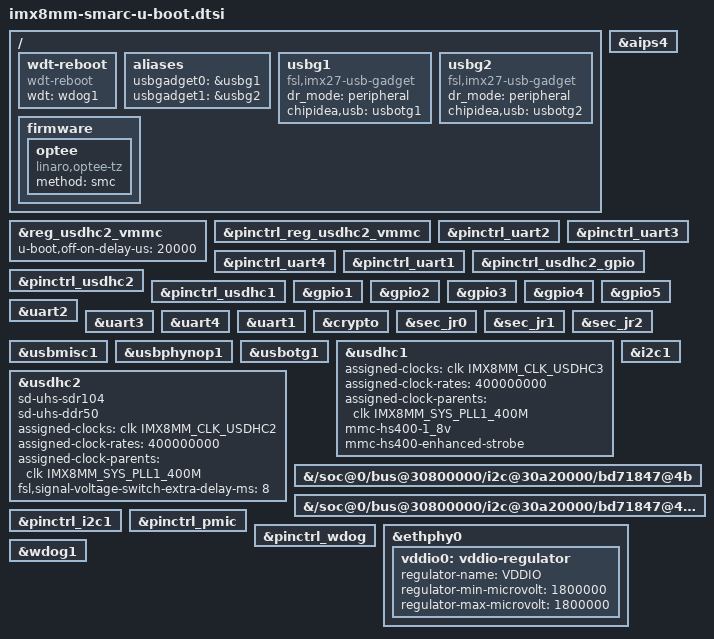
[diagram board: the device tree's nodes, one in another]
// SPDX-License-Identifier: GPL-2.0+
/*
 * Copyright 2019, 2021 NXP
 */

#include "imx8mm-u-boot.dtsi"

/ {
	wdt-reboot {
		compatible = "wdt-reboot";
		wdt = <&wdog1>;
		bootph-pre-ram;
	};

	aliases {
		usbgadget0 = &usbg1;
		usbgadget1 = &usbg2;
	};

	usbg1: usbg1 {
		compatible = "fsl,imx27-usb-gadget";
		dr_mode = "peripheral";
		chipidea,usb = <&usbotg1>;
		status = "okay";
	};

	usbg2: usbg2 {
		compatible = "fsl,imx27-usb-gadget";
		dr_mode = "peripheral";
		chipidea,usb = <&usbotg2>;
		status = "okay";
	};

	firmware {
		optee {
			compatible = "linaro,optee-tz";
			method = "smc";
		};
	};
};

&aips4 {
	bootph-pre-ram;
};

&reg_usdhc2_vmmc {
	u-boot,off-on-delay-us = <20000>;
	bootph-pre-ram;
};

&pinctrl_reg_usdhc2_vmmc {
	bootph-pre-ram;
};

&pinctrl_uart2 {
	bootph-pre-ram;
};

&pinctrl_uart3 {
	bootph-pre-ram;
};

&pinctrl_uart4 {
	bootph-pre-ram;
};

&pinctrl_uart1 {
	bootph-pre-ram;
};

&pinctrl_usdhc2_gpio {
	bootph-pre-ram;
};

&pinctrl_usdhc2 {
	bootph-pre-ram;
};

&pinctrl_usdhc1 {
	bootph-pre-ram;
};

&gpio1 {
	bootph-pre-ram;
};

&gpio2 {
	bootph-pre-ram;
};

&gpio3 {
	bootph-pre-ram;
};

&gpio4 {
	bootph-pre-ram;
};

&gpio5 {
	u-boot,dm-spl;
};

&uart2 {
	u-boot,dm-spl;
};

&uart3 {
	u-boot,dm-spl;
};

&uart4 {
	u-boot,dm-spl;
};

&uart1 {
	u-boot,dm-spl;
};

&crypto {
	u-boot,dm-spl;
};

&sec_jr0 {
	u-boot,dm-spl;
};

&sec_jr1 {
	u-boot,dm-spl;
};

&sec_jr2 {
	u-boot,dm-spl;
};

&usbmisc1 {
	u-boot,dm-spl;
};

&usbphynop1 {
	u-boot,dm-spl;
};

&usbotg1 {
	u-boot,dm-spl;
};

&usdhc1 {
	u-boot,dm-spl;
	assigned-clocks = <&clk IMX8MM_CLK_USDHC1>;
	assigned-clock-rates = <400000000>;
	assigned-clock-parents = <&clk IMX8MM_SYS_PLL1_400M>;
};

&usdhc2 {
	u-boot,dm-spl;
	sd-uhs-sdr104;
	sd-uhs-ddr50;
	assigned-clocks = <&clk IMX8MM_CLK_USDHC2>;
	assigned-clock-rates = <400000000>;
	assigned-clock-parents = <&clk IMX8MM_SYS_PLL1_400M>;
	fsl,signal-voltage-switch-extra-delay-ms = <8>;
};

&usdhc1 {
	u-boot,dm-spl;
	mmc-hs400-1_8v;
	mmc-hs400-enhanced-strobe;
	assigned-clocks = <&clk IMX8MM_CLK_USDHC3>;
	assigned-clock-rates = <400000000>;
	assigned-clock-parents = <&clk IMX8MM_SYS_PLL1_400M>;
};

&i2c1 {
	u-boot,dm-spl;
};

&{/soc@0/bus@30800000/i2c@30a20000/bd71847@4b} {
	u-boot,dm-spl;
};

&{/soc@0/bus@30800000/i2c@30a20000/bd71847@4b/regulators} {
	u-boot,dm-spl;
};

&pinctrl_i2c1 {
	u-boot,dm-spl;
};

&pinctrl_pmic {
	u-boot,dm-spl;
};

&pinctrl_wdog {
	u-boot,dm-spl;
};

&ethphy0 {
	vddio0: vddio-regulator {
		regulator-name = "VDDIO";
		regulator-min-microvolt = <1800000>;
		regulator-max-microvolt = <1800000>;
	};
};

&wdog1 {
	u-boot,dm-spl;
};

&usbotg1 {
	status = "okay";
};
